# PIC32MX430F064L device description
Architecture: MIPS; Family: PIC32MX; Series: PIC32MX
Registers are 32-bit, read-write, no defined reset value unless marked. A register's access mark holds for its fields unless they carry their own. Offsets are from the block's base; [hi:lo] are bit positions; {n}, {i} and the like mark numbered series; 'fields as' and 'values as' point back to an identical list.

## FUSECONFIG
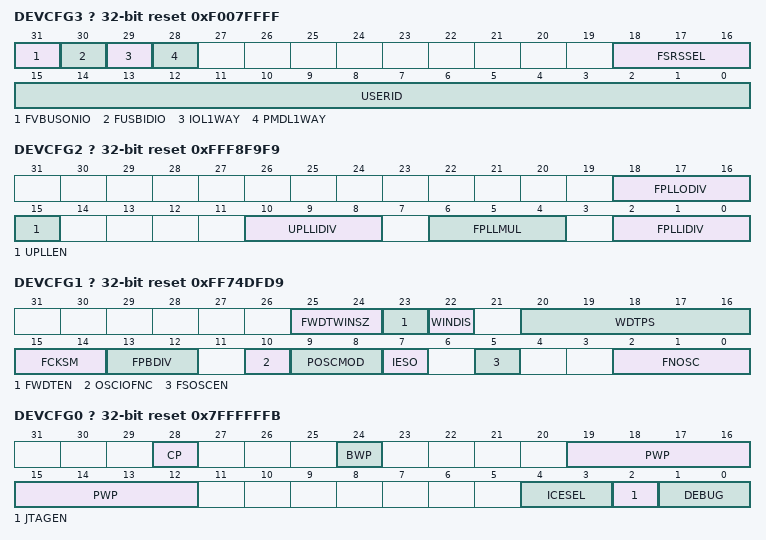
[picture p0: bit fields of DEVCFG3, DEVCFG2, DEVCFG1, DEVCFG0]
? DEVCFG3 size not given access not given reset 0xF007FFFF — Device Configuration Word 3
  [31] FVBUSONIO — USB VBUS_ON Selection bit
    1=ON (VBUSON pin is controlled by the USB module); 0=OFF (VBUSON pin is controlled by the port function)
  [30] FUSBIDIO — USB USBID Selection bit
    1=ON (USBID pin is controlled by the USB module); 0=OFF (USBID pin is controlled by the port function)
  [29] IOL1WAY — Peripheral Pin Select Configuration bit
    1=ON (Allow only one reconfiguration); 0=OFF (Allow multiple reconfigurations)
  [28] PMDL1WAY — Peripheral Module Disable Configuration bit
    values as IOL1WAY
  [18:16] FSRSSEL — Shadow Register Set Priority Select bit
    {v}=PRIORITY_{v} (SRS Priority {v}) (v=0..7)
  [15:0] USERID
    ?=User ID
? DEVCFG2 size not given access not given reset 0xFFF8F9F9 — Device Configuration Word 2
  [18:16] FPLLODIV — Default PLL Output Divisor bits
    0=DIV_1 (PLL Divide by 1); 1=DIV_2 (PLL Divide by 2); 2=DIV_4 (PLL Divide by 4); 3=DIV_8 (PLL Divide by 8); 4=DIV_16 (PLL Divide by 16); 5=DIV_32 (PLL Divide by 32); 6=DIV_64 (PLL Divide by 64); 7=DIV_256 (PLL Divide by 256)
  [15] UPLLEN — USB PLL Enable bit
    0=ON (Enable USB PLL); 1=OFF (Disable and bypass USB PLL)
  [10:8] UPLLIDIV — USB PLL Input Divider bits
    7=DIV_12 (12x Divider); 6=DIV_10 (10x Divider); {v}=DIV_{v+1} ({v+1}x Divider) (v=0..5)
  [6:4] FPLLMUL — PLL Multiplier bits
    {v}=MUL_{v+15} ({v+15}x Multiplier) (v=0..6); 7=MUL_24 (24x Multiplier)
  [2:0] FPLLIDIV — PLL Input Divider bits
    {v}=DIV_{v+1} ({v+1}x Divider) (v=0..5); 6=DIV_10 (10x Divider); 7=DIV_12 (12x Divider)
? DEVCFG1 size not given access not given reset 0xFF74DFD9 — Device Configuration Word 1
  [25:24] FWDTWINSZ — Watchdog Timer Window Size bits
    0=WINSZ_75 (Window Size is 75%); 1=WINSZ_50 (Window Size is 50%); 2=WINSZ_37 (Window Size is 37.5%); 3=WINSZ_25 (Window Size is 25%)
  [23] FWDTEN — Watchdog Timer Enable bit
    0=OFF (Watchdog Timer is not enabled; it can be enabled in software); 1=ON (Watchdog Timer is enabled and cannot be disabled by software)
  [22] WINDIS — Watchdog Timer Window Enable bit
    0=ON (Watchdog Timer is in Window Mode); 1=OFF (Watchdog Timer is in Non-Window Mode)
  [20:16] WDTPS — Watchdog Timer Postscale Select bits
    0=PS1 (1:1); 1=PS2 (1:2); 2=PS4 (1:4); 3=PS8 (1:8); 4=PS16 (1:16); 5=PS32 (1:32); 6=PS64 (1:64); 7=PS128 (1:128); 8=PS256 (1:256); 9=PS512 (1:512); 10=PS1024 (1:1024); 11=PS2048 (1:2048); 12=PS4096 (1:4096); 13=PS8192 (1:8192); 14=PS16384 (1:16384); 15=PS32768 (1:32768); 16=PS65536 (1:65536); 17=PS131072 (1:131072); 18=PS262144 (1:262144); 19=PS524288 (1:524288); 20=PS1048576 (1:1048576)
  [15:14] FCKSM — Clock Switching and Monitor Selection Configuration bits
    0=CSECME (Clock Switch Enable, FSCM Enabled); 1=CSECMD (Clock Switch Enable, FSCM Disabled); 3=CSDCMD (Clock Switch Disable, FSCM Disabled)
  [13:12] FPBDIV — Peripheral Bus Clock Divisor Default Value bits
    0=DIV_1 (Pb_Clk is Sys_Clk/1); 1=DIV_2 (Pb_Clk is Sys_Clk/2); 2=DIV_4 (Pb_Clk is Sys_Clk/4); 3=DIV_8 (Pb_Clk is Sys_Clk/8)
  [10] OSCIOFNC — CLKO Enable Configuration bit
    1=OFF (CLKO output is disabled); 0=ON (CLKO output signal active on the OSCO pin)
  [9:8] POSCMOD — Primary Oscillator Configuration bits
    0=EC (External clock mode); 1=XT (XT osc mode); 2=HS (HS osc mode); 3=OFF (Primary osc disabled)
  [7] IESO — Internal External Switchover bit
    0=OFF (Disabled); 1=ON (Enabled)
  [5] FSOSCEN — Secondary Oscillator Enable bit
    0=OFF (Disabled); 1=ON (Enabled)
  [2:0] FNOSC — Oscillator Selection bits
    0=FRC (Fast RC Osc (FRC)); 1=FRCPLL (Fast RC Osc with PLL); 2=PRI (Primary Osc (XT,HS,EC)); 3=PRIPLL (Primary Osc w/PLL (XT+,HS+,EC+PLL)); 4=SOSC (Low Power Secondary Osc (SOSC)); 5=LPRC (Low Power RC Osc (LPRC)); 6=FRCDIV16 (Fast RC Osc w/Div-by-16 (FRC/16)); 7=FRCDIV (Fast RC Osc w/Div-by-N (FRCDIV))
? DEVCFG0 size not given access not given reset 0x7FFFFFFB — Device Configuration Word 0
  [28] CP — Code-Protect bit
    0=ON (Protection Enabled); 1=OFF (Protection Disabled)
  [24] BWP — Boot Flash Write-Protect bit
    0=ON (Protection Enabled); 1=OFF (Protection Disabled)
  [19:12] PWP — Program Flash Write-Protect bits
    255=OFF (Disable); 254=PWP4K (First 4K); 253=PWP8K (First 8K); 252=PWP12K (First 12K); 251=PWP16K (First 16K); 250=PWP20K (First 20K); 249=PWP24K (First 24K); 248=PWP28K (First 28K); 247=PWP32K (First 32K); 246=PWP36K (First 36K); 245=PWP40K (First 40K); 244=PWP44K (First 44K); 243=PWP48K (First 48K); 242=PWP52K (First 52K); 241=PWP56K (First 56K); 240=PWP60K (First 60K); 239=PWP64K (First 64K); 238=PWP68K (First 68K); 237=PWP72K (First 72K); 236=PWP76K (First 76K); 235=PWP80K (First 80K); 234=PWP84K (First 84K); 233=PWP88K (First 88K); 232=PWP92K (First 92K); 231=PWP96K (First 96K); 230=PWP100K (First 100K); 229=PWP104K (First 104K); 228=PWP108K (First 108K); 227=PWP112K (First 112K); 226=PWP116K (First 116K); 225=PWP120K (First 120K); 224=PWP124K (First 124K); 223=PWP128K (First 128K); 222=PWP132K (First 132K); 221=PWP136K (First 136K); 220=PWP140K (First 140K); 219=PWP144K (First 144K); 218=PWP148K (First 148K); 217=PWP152K (First 152K); 216=PWP156K (First 156K); 215=PWP160K (First 160K); 214=PWP164K (First 164K); 213=PWP168K (First 168K); 212=PWP172K (First 172K); 211=PWP176K (First 176K); 210=PWP180K (First 180K); 209=PWP184K (First 184K); 208=PWP188K (First 188K); 207=PWP192K (First 192K); 206=PWP196K (First 196K); 205=PWP200K (First 200K); 204=PWP204K (First 204K); 203=PWP208K (First 208K); 202=PWP212K (First 212K); 201=PWP216K (First 216K); 200=PWP220K (First 220K); 199=PWP224K (First 224K); 198=PWP228K (First 228K); 197=PWP232K (First 232K); 196=PWP236K (First 236K); 195=PWP240K (First 240K); 194=PWP244K (First 244K); 193=PWP248K (First 248K); 192=PWP252K (First 252K); 191=PWP256K (First 256K); 190=PWP260K (First 260K); 189=PWP264K (First 264K); 188=PWP268K (First 268K); 187=PWP272K (First 272K); 186=PWP276K (First 276K); 185=PWP280K (First 280K); 184=PWP284K (First 284K); 183=PWP288K (First 288K); 182=PWP292K (First 292K); 181=PWP296K (First 296K); 180=PWP300K (First 300K); 179=PWP304K (First 304K); 178=PWP308K (First 308K); 177=PWP312K (First 312K); 176=PWP316K (First 316K); 175=PWP320K (First 320K); 174=PWP324K (First 324K); 173=PWP328K (First 328K); 172=PWP332K (First 332K); 171=PWP336K (First 336K); 170=PWP340K (First 340K); 169=PWP344K (First 344K); 168=PWP348K (First 348K); 167=PWP352K (First 352K); 166=PWP356K (First 356K); 165=PWP360K (First 360K); 164=PWP364K (First 364K); 163=PWP368K (First 368K); 162=PWP372K (First 372K); 161=PWP376K (First 376K); 160=PWP380K (First 380K); 159=PWP384K (First 384K); 158=PWP388K (First 388K); 157=PWP392K (First 392K); 156=PWP396K (First 396K); 155=PWP400K (First 400K); 154=PWP404K (First 404K); 153=PWP408K (First 408K); 152=PWP412K (First 412K); 151=PWP416K (First 416K); 150=PWP420K (First 420K); 149=PWP424K (First 424K); 148=PWP428K (First 428K); 147=PWP432K (First 432K); 146=PWP436K (First 436K); 145=PWP440K (First 440K); 144=PWP444K (First 444K); 143=PWP448K (First 448K); 142=PWP452K (First 452K); 141=PWP456K (First 456K); 140=PWP460K (First 460K); 139=PWP464K (First 464K); 138=PWP468K (First 468K); 137=PWP472K (First 472K); 136=PWP476K (First 476K); 135=PWP480K (First 480K); 134=PWP484K (First 484K); 133=PWP488K (First 488K); 132=PWP492K (First 492K); 131=PWP496K (First 496K); 130=PWP500K (First 500K); 129=PWP504K (First 504K); 128=PWP508K (First 508K); 127=PWP512K (First 512K)
  [4:3] ICESEL — In-Circuit Emulator/Debugger Communication Channel Select bits
    3=ICS_PGx1 (Communicate on PGEC1/PGED1); 2=ICS_PGx2 (Communicate on PGEC2/PGED2); 1=ICS_PGx3 (Communicate on PGEC3/PGED3)
  [2] JTAGEN — JTAG Enable bit
    1=ON (JTAG Port Enabled); 0=OFF (JTAG Disabled)
  [1:0] DEBUG — Background Debugger Enable bits (forced to 11 if code-protect is enabled)
    0=ON (Debugger is Enabled); 3=OFF (Debugger is Disabled)

## Notices in the file
Copyright (c) 2019 Microchip Technology Inc.
SPDX-License-Identifier: Apache-2.0
Licensed under the Apache License, Version 2.0 (the "License");
you may not use this file except in compliance with the License.
You may obtain a copy of the License at
http://www.apache.org/licenses/LICENSE-2.0
Unless required by applicable law or agreed to in writing, software
distributed under the License is distributed on an "AS IS" BASIS,
WITHOUT WARRANTIES OR CONDITIONS OF ANY KIND, either express or implied.
See the License for the specific language governing permissions and
limitations under the License.
